# STM32U385 register map
File version: 1.0
CPU: CM33 r0p1, little endian, MPU, FPU, 4 interrupt priority bits
Registers are 32-bit, read-write, reset 0x0 unless marked. A register's access mark holds for its fields unless they carry their own. Offsets are from the block's base; [hi:lo] are bit positions; {n}, {i} and the like mark numbered series; 'fields as' and 'values as' point back to an identical list.

## USB — USB Address block
Base 0x40016000
Same registers: SEC_USB 0x50016000
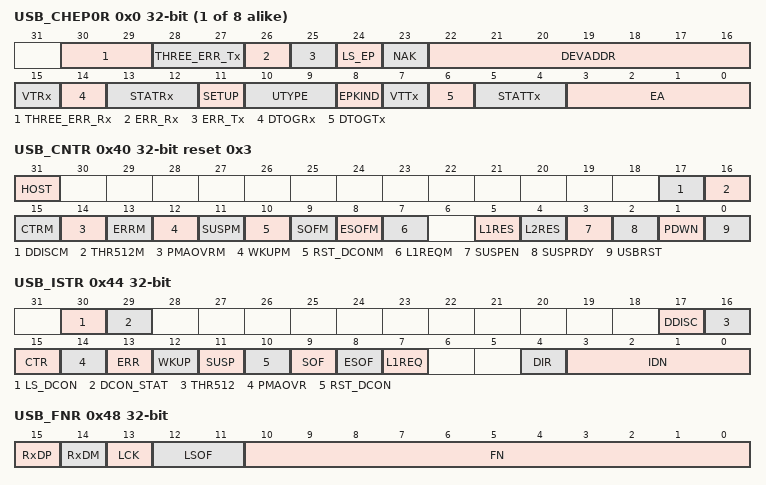
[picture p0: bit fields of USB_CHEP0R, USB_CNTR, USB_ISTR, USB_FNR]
{0x0+4i} USB_CHEP{i}R access per field (i=0..7) — USB endpoint/channel {i} register
  [30:29] THREE_ERR_Rx rw — - Host mode This bit is set by the hardware when 3 consecutive transaction errors occurred on the USB bus for an IN transaction. THREE_ERR_Rx is not generated for isochronous transactions. The software can only clear this bit. Coding of the received error: 00: Less than 3 errors received. 01: More than 3 errors received, last error is timeout error. 10: More than 3 errors received, last error is data error (CRC error). 11: More than 3 errors received, last error is protocol error (invalid PID, false EOP, bitstuffing error, SYNC error).
    0=Less than 3 errors received; 1=More than 3 errors received, last error is timeout error; 2=More than 3 errors received, last error is data error (CRC error); 3=More than 3 errors received, last error is protocol error (invalid PID, false EOP, bitstuffing error, SYNC error)
  [28:27] THREE_ERR_Tx rw — - Host mode This bit is set by the hardware when 3 consecutive transaction errors occurred on the USB bus for an OUT transaction. THREE_ERR_Tx is not generated for isochronous transactions. The software can only clear this bit. Coding of the received error: 00: Less than 3 errors received. 01: More than 3 errors received, last error is timeout error. 10: More than 3 errors received, last error is data error (CRC error). 11: More than 3 errors received, last error is protocol error (invalid PID, false EOP, bitstuffing error, SYNC error).
    values as THREE_ERR_Rx
  [26] ERR_Rx rw — - Host mode This bit is set by the hardware when an error (for example no answer by the device, CRC error, bit stuffing error, framing format violation, etc.) has occurred during an IN transaction on this channel. The software can only clear this bit. If the ERRM bit in USB_CNTR register is set, a generic interrupt condition is generated together with the channel related flag, which is always activated.
  [25] ERR_Tx rw — - Host mode This bit is set by the hardware when an error (for example no answer by the device, CRC error, bit stuffing error, framing format violation, etc.) has occurred during an OUT or SETUP transaction on this channel. The software can only clear this bit. If the ERRM bit in USB_CNTR register is set, a generic interrupt condition is generated together with the channel related flag, which is always activated.
  [24] LS_EP rw — - Host mode This bit is set by the software to send an LS transaction to the corresponding endpoint. 0: Full speed endpoint 1: Low speed endpoint
    0=Full speed endpoint; 1=Low speed endpoint
  [23] NAK rw — - Host mode This bit is set by the hardware when a device responds with a NAK. Software can use this bit to monitor the number of NAKs received from a device.
  [22:16] DEVADDR rw — - Host mode Device address assigned to the endpoint during the enumeration process.
  [15] VTRx rw — - Device mode This bit is set by the hardware when an OUT/SETUP transaction is successfully completed on this endpoint; the software can only clear this bit. If the CTRM bit in USB_CNTR register is set accordingly, a generic interrupt condition is generated together with the endpoint related interrupt condition, which is always activated. The type of occurred transaction, OUT or SETUP, can be determined from the SETUP bit described below. A transaction ended with a NAK or STALL handshake does not set this bit, since no data is actually transferred, as in the case of protocol errors or data toggle mismatches. This bit is read/write but only 0 can be written, writing 1 has no effect. - Host mode This bit is set by the hardware when an IN transaction is successfully completed on this channel. The software can only clear this bit. If the CTRM bit in USB_CNTR register is set a generic interrupt condition is generated together with the channel related flag, which is always activated. If double buffering is disabled, ACK answer is reported by application reading the DISABLE state from the STATRx field of this register. Host application should read received data from USBRAM and re-arm the channel by writing VALID to the STATRx field of this register. If double buffering is enabled, ACK answer is reported by application reading VALID state from the STATRx field of this register. Host application should read received data from USBRAM and toggle the DTOGTx bit of this register. Errors can be seen via the bits ERR_Rx (host mode only). This bit is read/write but only 0 can be written, writing 1 has no effect.
  [14] DTOGRx wo — If the endpoint/channel is not isochronous, this bit contains the expected value of the data toggle bit (0 = DATA0, 1 = DATA1) for the next data packet to be received. Hardware toggles this bit, when the ACK handshake is sent following a data packet reception having a matching data PID value; if the endpoint is defined as a control one, hardware clears this bit at the reception of a SETUP PID received from host (in device mode), while it sets this bit to 1 when SETUP transaction is acknowledged by device (in host mode). If the endpoint/channel is using the double-buffering feature this bit is used to support packet buffer swapping too (Refer to less than xe1 [Double-buffered_endpoints_and_usage_in_Device_mode]/>). If the endpoint/channel is isochronous, this bit is used only to support packet buffer swapping for data transmission since no data toggling is used for this kind of channels/endpoints and only DATA0 packet are transmitted (Refer to less than xe2 [Isochronous_transfers_in_Device_mode]/>). Hardware toggles this bit just after the end of data packet reception, since no handshake is used for isochronous transfers. This bit can also be toggled by the software to initialize its value (mandatory when the endpoint is not a control one) or to force specific data toggle/packet buffer usage. When the application software writes 0, the value of DTOGRx remains unchanged, while writing 1 makes the bit value toggle. This bit is read/write but it can be only toggled by writing 1. - A transaction ended with a NAK sets this bit and NAK answer is reported to application reading the NAK state from the STATRx field of this register. One NAKed transaction keeps pending and is automatically retried by the host at the next frame, or the host can immediately retry by resetting STATRx state to VALID. - A transaction ended by STALL handshake sets this bit and the STALL answer is reported to application reading the STALL state from the STATRx field of this register. Host application should consequently disable the channel and re-enumerate. - A transaction ended with ACK handshake sets this bit - A transaction ended with error sets this bit.
  [13:12] STATRx wo — - Device mode These bits contain information about the endpoint status, which are listed in less than xe3 []/>.
    0=DISABLED: all reception requests addressed to this endpoint/channel are ignored; 1=STALL: Device mode: the endpoint is stalled and all reception requests result in a STALL handshake. Host mode: this indicates that the device has STALLed the channel.; 2=NAK: Device mode: the endpoint is NAKed and all reception requests result in a NAK handshake. Host mode: this indicates that the device has NAKed the reception request.; 3=VALID: this endpoint/channel is enabled for reception
  [11] SETUP ro — - Device mode This bit is read-only and it is set by the hardware when the last completed transaction is a SETUP. This bit changes its value only for control endpoints. It must be examined, in the case of a successful receive transaction (VTRx event), to determine the type of transaction occurred. To protect the interrupt service routine from the changes in SETUP bits due to next incoming tokens, this bit is kept frozen while VTRx bit is at 1; its state changes when VTRx is at 0. This bit is read-only. - Host mode This bit is set by the software to send a SETUP transaction on a control endpoint. This bit changes its value only for control endpoints. It is cleared by hardware when the SETUP transaction is acknowledged and VTTx interrupt generated.
  [10:9] UTYPE rw — These bits configure the behavior of this endpoint/channel as described in less than xe4 []/>. Channel0/Endpoint0 must always be a control endpoint/channel and each USB function must have at least one control endpoint/channel which has address 0, but there may be other control channels/endpoints if required. Only control channels/endpoints handle SETUP transactions, which are ignored by endpoints of other kinds. SETUP transactions cannot be answered with NAK or STALL. If a control endpoint/channel is defined as NAK, the USB peripheral does not answer, simulating a receive error, in the receive direction when a SETUP transaction is received. If the control endpoint/channel is defined as STALL in the receive direction, then the SETUP packet is accepted anyway, transferring data and issuing the CTR interrupt. The reception of OUT transactions is handled in the normal way, even if the endpoint/channel is a control one. Bulk and interrupt endpoints have very similar behavior and they differ only in the special feature available using the EPKIND configuration bit. The usage of isochronous channels/endpoints is explained in less than xe2 [Isochronous_transfers_in_Device_mode]/> 00: BULK-EPKIND meaning : DBL_BUF 01: CONTROL-EPKIND meaning :STATUS_OUT 10: ISO-EPKIND meaning SBUF_ISO: This bit is set by the software to enable the single-buffering feature for isochronous endpoint 11: INTERRUPT-EPKIND meaning : Not used
    0=BULK-EPKIND meaning : DBL_BUF; 1=CONTROL-EPKIND meaning :STATUS_OUT; 2=ISO-EPKIND meaning SBUF_ISO: This bit is set by the software to enable the single-buffering feature for isochronous endpoint; 3=INTERRUPT-EPKIND meaning : Not used
  [8] EPKIND rw — The meaning of this bit depends on the endpoint/channel type configured by the UTYPE bits. less than xe5 []/> summarizes the different meanings. DBL_BUF: This bit is set by the software to enable the double-buffering feature for this bulk endpoint. The usage of double-buffered bulk endpoints is explained in less than xe1 [Double-buffered_endpoints_and_usage_in_Device_mode]/>. STATUS_OUT: This bit is set by the software to indicate that a status out transaction is expected: in this case all OUT transactions containing more than zero data bytes are answered 'STALL' instead of 'ACK'. This bit may be used to improve the robustness of the application to protocol errors during control transfers and its usage is intended for control endpoints only. When STATUS_OUT is reset, OUT transactions can have any number of bytes, as required.
  [7] VTTx rw — - Device mode This bit is set by the hardware when an IN transaction is successfully completed on this endpoint; the software can only clear this bit. If the CTRM bit in the USB_CNTR register is set accordingly, a generic interrupt condition is generated together with the endpoint related interrupt condition, which is always activated. A transaction ended with a NAK or STALL handshake does not set this bit, since no data is actually transferred, as in the case of protocol errors or data toggle mismatches. This bit is read/write but only 0 can be written. - Host mode Same as VTRx behavior but for USB OUT and SETUP transactions.
  [6] DTOGTx wo — If the endpoint/channel is non-isochronous, this bit contains the required value of the data toggle bit (0 = DATA0, 1 = DATA1) for the next data packet to be transmitted. Hardware toggles this bit when the ACK handshake is received from the USB host, following a data packet transmission. If the endpoint/channel is defined as a control one, hardware sets this bit to 1 at the reception of a SETUP PID addressed to this endpoint (in device mode) or when a SETUP transaction is acknowledged by the device (in host mode). If the endpoint/channel is using the double buffer feature, this bit is used to support packet buffer swapping too (Refer to less than xe1 [Double-buffered_endpoints_and_usage_in_Device_mode]/>). If the endpoint/channel is isochronous, this bit is used to support packet buffer swapping since no data toggling is used for this sort of endpoints and only DATA0 packet are transmitted (refer to less than xe2 [Isochronous_transfers_in_Device_mode]/>). Hardware toggles this bit just after the end of data packet transmission, since no handshake is used for isochronous transfers. This bit can also be toggled by the software to initialize its value (mandatory when the endpoint/channel is not a control one) or to force a specific data toggle/packet buffer usage. When the application software writes 0, the value of DTOGTx remains unchanged, while writing 1 makes the bit value to toggle. This bit is read/write but it can only be toggled by writing 1.
  [5:4] STATTx wo — - Device mode These bits contain the information about the endpoint status, listed in less than xe6 []/>.
    0=DISABLED: all transmission requests addressed to this endpoint/channel are ignored; 1=STALL: Device mode: the endpoint is stalled and all transmission requests result in a STALL handshake. Host mode: this indicates that the device has STALLed the channel.; 2=NAK: Device mode: the endpoint is NAKed and all transmission requests result in a NAK handshake. Host mode: this indicates that the device has NAKed the transmission request.; 3=VALID: this endpoint/channel is enabled for transmission
  [3:0] EA rw — - Device mode Software must write in this field the 4-bit address used to identify the transactions directed to this endpoint. A value must be written before enabling the corresponding endpoint. - Host mode Software must write in this field the 4-bit address used to identify the channel addressed by the host transaction.
0x40 USB_CNTR access per field reset 0x3 — USB control register
  [31] HOST rw — HOST bit selects betweens host or device USB mode of operation. It must be set before enabling the USB peripheral by the function enable bit. 0: USB Device function 1: USB host function
    0=USB Device function; 1=USB host function
  [17] DDISCM rw — - Host mode 0: Device disconnection interrupt disabled 1: Device disconnection interrupt enabled
    0=Device disconnection interrupt disabled; 1=Device disconnection interrupt enabled
  [16] THR512M rw — None 0: 512 byte threshold interrupt disabled 1: 512 byte threshold interrupt enabled
    0=512 byte threshold interrupt disabled; 1=512 byte threshold interrupt enabled
  [15] CTRM rw — None 0: Correct transfer (CTR) interrupt disabled. 1: CTR interrupt enabled, an interrupt request is generated when the corresponding bit in the USB_ISTR register is set.
    0=Correct transfer (CTR) interrupt disabled; 1=CTR interrupt enabled, an interrupt request is generated when the corresponding bit in the USB_ISTR register is set
  [14] PMAOVRM rw — None 0: PMAOVR interrupt disabled. 1: PMAOVR interrupt enabled, an interrupt request is generated when the corresponding bit in the USB_ISTR register is set.
    0=PMAOVR interrupt disabled; 1=PMAOVR interrupt enabled, an interrupt request is generated when the corresponding bit in the USB_ISTR register is set
  [13] ERRM rw — None 0: ERR interrupt disabled. 1: ERR interrupt enabled, an interrupt request is generated when the corresponding bit in the USB_ISTR register is set.
    0=ERR interrupt disabled; 1=ERR interrupt enabled, an interrupt request is generated when the corresponding bit in the USB_ISTR register is set
  [12] WKUPM rw — None 0: WKUP interrupt disabled. 1: WKUP interrupt enabled, an interrupt request is generated when the corresponding bit in the USB_ISTR register is set.
    0=WKUP interrupt disabled; 1=WKUP interrupt enabled, an interrupt request is generated when the corresponding bit in the USB_ISTR register is set
  [11] SUSPM rw — None 0: Suspend mode request (SUSP) interrupt disabled. 1: SUSP interrupt enabled, an interrupt request is generated when the corresponding bit in the USB_ISTR register is set.
    0=Suspend mode request (SUSP) interrupt disabled; 1=SUSP interrupt enabled, an interrupt request is generated when the corresponding bit in the USB_ISTR register is set
  [10] RST_DCONM rw — None 0: RESET interrupt disabled. 1: RESET interrupt enabled, an interrupt request is generated when the corresponding bit in the USB_ISTR register is set.
    0=RESET interrupt disabled; 1=RESET interrupt enabled, an interrupt request is generated when the corresponding bit in the USB_ISTR register is set
  [9] SOFM rw — None 0: SOF interrupt disabled. 1: SOF interrupt enabled, an interrupt request is generated when the corresponding bit in the USB_ISTR register is set.
    0=SOF interrupt disabled; 1=SOF interrupt enabled, an interrupt request is generated when the corresponding bit in the USB_ISTR register is set
  [8] ESOFM rw — None 0: Expected start of frame (ESOF) interrupt disabled. 1: ESOF interrupt enabled, an interrupt request is generated when the corresponding bit in the USB_ISTR register is set.
    0=Expected start of frame (ESOF) interrupt disabled; 1=ESOF interrupt enabled, an interrupt request is generated when the corresponding bit in the USB_ISTR register is set
  [7] L1REQM rw — None 0: LPM L1 state request (L1REQ) interrupt disabled. 1: L1REQ interrupt enabled, an interrupt request is generated when the corresponding bit in the USB_ISTR register is set.
    0=LPM L1 state request (L1REQ) interrupt disabled; 1=L1REQ interrupt enabled, an interrupt request is generated when the corresponding bit in the USB_ISTR register is set
  [5] L1RES rw — - Device mode Software sets this bit to send a LPM L1 50 us remote wakeup signaling to the host. After the signaling ends, this bit is cleared by hardware. 0: No effect 1: Send 50 us remote-wakeup signaling to host
    0=No effect; 1=Send 50 us remote-wakeup signaling to host
  [4] L2RES rw — - Device mode The microcontroller can set this bit to send remote wake-up signaling to the host. It must be activated, according to USB specifications, for no less than 1 ms and no more than 15 ms after which the host PC is ready to drive the resume sequence up to its end. - Host mode Software sets this bit to send resume signaling to the device. Software clears this bit to send end of resume to device and restart SOF generation. In the context of remote wake up, this bit is to be set following the WAKEUP interrupt. 0: No effect 1: Send L2 resume signaling to device
    0=No effect; 1=Send L2 resume signaling to device
  [3] SUSPEN rw — - Condition: Device mode Software can set this bit when the SUSP interrupt is received, which is issued when no traffic is received by the USB peripheral for 3 ms. Software can also set this bit when the L1REQ interrupt is received with positive acknowledge sent. As soon as the suspend state is propagated internally all device activity is stopped, USB clock is gated, USB transceiver is set into low power mode and the SUSPRDY bit is set by hardware. In the case that device application wants to pursue more aggressive power saving by stopping the USB clock source and by moving the microcontroller to stop mode, as in the case of bus powered device application, it must first wait few cycles to see the SUSPRDY = 1 acknowledge the suspend request. This bit is cleared by hardware simultaneous with the WAKEUP flag set. Software can set this bit when host application has nothing scheduled for the next frames and wants to enter long term power saving. When set, it stops immediately SOF generation and any other host activity, gates the USB clock and sets the transceiver in low power mode. If any USB transaction is on-going at the time SUSPEN is set, suspend is entered at the end of the current transaction. As soon as suspend state is propagated internally and gets effective the SUSPRDY bit is set. In the case that host application wants to pursue more aggressive power saving by stopping the USB clock source and by moving the micro-controller to STOP mode, it must first wait few cycles to see SUSPRDY=1 acknowledge to the suspend request. This bit is cleared by hardware simultaneous with the WAKEUP flag set. Condition: Device mode 0: No effect 1: Enter L1/L2 suspend Condition: Host mode 0: No effect 1: Enter L1/L2 suspend
    0=B_0x0_COND1 (COND1 is [Device mode] No effect); 1=B_0x1_COND1 (COND1 is [Device mode] Enter L1/L2 suspend)
  [2] SUSPRDY ro — This bit is set by hardware as soon as the suspend state entered through the SUSPEN control gets internally effective. In this state USB activity is suspended, USB clock is gated, transceiver is set in low power mode by disabling the differential receiver. Only asynchronous wakeup logic and single ended receiver is kept alive to detect remote wakeup or resume events. Software must poll this bit to confirm it to be set before any STOP mode entry. This bit is cleared by hardware simultaneously to the WAKEUP flag being set. 0: Normal operation 1: Suspend state
    0=Normal operation; 1=Suspend state
  [1] PDWN rw — This bit is used to completely switch off all USB-related analog parts if it is required to completely disable the USB peripheral for any reason. When this bit is set, the USB peripheral is disconnected from the transceivers and it cannot be used. 0: Exit power down 1: Enter power down mode
    0=Exit power down; 1=Enter power down mode
  [0] USBRST rw — - Condition: Device mode Software can set this bit to reset the USB core, exactly as it happens when receiving a RESET signaling on the USB.The USB peripheral, in response to a RESET, resets its internal protocol state machine. Reception and transmission are disabled until the RST_DCON bit is cleared. All configuration registers do not reset: the microcontroller must explicitly clear these registers (this is to ensure that the RST_DCON interrupt can be safely delivered, and any transaction immediately followed by a RESET can be completed). The function address and endpoint registers are reset by an USB reset event. Software sets this bit to drive USB reset state on the bus and initialize the device. USB reset terminates as soon as this bit is cleared by software. Condition: Device mode 0: No effect 1: USB core is under reset Condition: Host mode 0: No effect 1: USB reset driven
    0=B_0x0_COND1 (COND1 is [Device mode] No effect); 1=B_0x1_COND1 (COND1 is [Device mode] USB core is under reset)
0x44 USB_ISTR access per field — USB interrupt status register
  [30] LS_DCON ro — - Host mode: This bit is set by hardware when an LS device connection is detected. Device connection is signaled after LS J-state is sampled for 22 consecutive cycles of the USB clock (48 MHz) from the unconnected state.
  [29] DCON_STAT ro — - Host mode: This bit contains information about device connection status. It is set by hardware when a LS/FS device is attached to the host while it is reset when the device is disconnected. 0: No device connected 1: FS or LS device connected to the host
    0=No device connected; 1=FS or LS device connected to the host
  [17] DDISC rw — - Host mode This bit is set when a device connection is detected. This bit is read/write but only 0 can be written and writing 1 has no effect.
  [16] THR512 rw — This bit is set to 1 by the hardware when 512 bytes have been transmitted or received during isochronous transfers. This bit is read/write but only 0 can be written and writing 1 has no effect. Note that no information is available to indicate the associated channel/endpoint, however in practice only one ISO endpoint/channel with such large packets can be supported, so that channel.
  [15] CTR ro — This bit is set by the hardware to indicate that an endpoint/channel has successfully completed a transaction; using DIR and IDN bits software can determine which endpoint/channel requested the interrupt. This bit is read-only.
  [14] PMAOVR rw — This bit is set if the microcontroller has not been able to respond in time to an USB memory request. The USB peripheral handles this event in the following way: During reception an ACK handshake packet is not sent, during transmission a bit-stuff error is forced on the transmitted stream; in both cases the host retries the transaction. The PMAOVR interrupt should never occur during normal operations. Since the failed transaction is retried by the host, the application software has the chance to speed-up device operations during this interrupt handling, to be ready for the next transaction retry; however this does not happen during isochronous transfers (no isochronous transaction is anyway retried) leading to a loss of data in this case. This bit is read/write but only 0 can be written and writing 1 has no effect.
  [13] ERR rw — This flag is set whenever one of the errors listed below has occurred: NANS:No ANSwer. The timeout for a host response has expired. CRC:Cyclic redundancy check error. One of the received CRCs, either in the token or in the data, was wrong. BST:Bit stuffing error. A bit stuffing error was detected anywhere in the PID, data, and/or CRC. FVIO:Framing format violation. A non-standard frame was received (EOP not in the right place, wrong token sequence, etc.). The USB software can usually ignore errors, since the USB peripheral and the PC host manage retransmission in case of errors in a fully transparent way. This interrupt can be useful during the software development phase, or to monitor the quality of transmission over the USB bus, to flag possible problems to the user (for example loose connector, too noisy environment, broken conductor in the USB cable and so on). This bit is read/write but only 0 can be written and writing 1 has no effect.
  [12] WKUP rw — This bit is set to 1 by the hardware when, during suspend mode, activity is detected that wakes up the USB peripheral. This event asynchronously clears the SUSPRDY bit in the CTLR register and activates the USB_WAKEUP line, which can be used to notify the rest of the device (for example wakeup unit) about the start of the resume process. This bit is read/write but only 0 can be written and writing 1 has no effect.
  [11] SUSP rw — - Device mode This bit is set by the hardware when no traffic has been received for 3 ms, indicating a suspend mode request from the USB bus. The suspend condition check is enabled immediately after any USB reset and it is disabled by the hardware when the suspend mode is active (SUSPEN=1) until the end of resume sequence. This bit is read/write but only 0 can be written and writing 1 has no effect.
  [10] RST_DCON rw — - Device mode This bit is set by hardware when an USB reset is released by the host and the bus returns to idle. USB reset state is internally detected after the sampling of 60 consecutive SE0 cycles. - Host mode This bit is set by hardware when device connection or device disconnection is detected. Device connection is signaled after J state is sampled for 22 cycles consecutively from unconnected state. Device disconnection is signaled after SE0 state is seen for 22 bit times consecutively from connected state.
  [9] SOF rw — This bit signals the beginning of a new USB frame and it is set when a SOF packet arrives through the USB bus. The interrupt service routine may monitor the SOF events to have a 1 ms synchronization event to the USB host and to safely read the USB_FNR register which is updated at the SOF packet reception (this could be useful for isochronous applications). This bit is read/write but only 0 can be written and writing 1 has no effect.
  [8] ESOF rw — - Device mode This bit is set by the hardware when an SOF packet is expected but not received. The host sends an SOF packet each 1 ms, but if the device does not receive it properly, the suspend timer issues this interrupt. If three consecutive ESOF interrupts are generated (for example three SOF packets are lost) without any traffic occurring in between, a SUSP interrupt is generated. This bit is set even when the missing SOF packets occur while the suspend timer is not yet locked. This bit is read/write but only 0 can be written and writing 1 has no effect.
  [7] L1REQ rw — - Device mode This bit is set by the hardware when LPM command to enter the L1 state is successfully received and acknowledged. This bit is read/write but only 0 can be written and writing 1 has no effect.
  [4] DIR ro — This bit is written by the hardware according to the direction of the successful transaction, which generated the interrupt request. If DIR bit = 0, VTTx bit is set in the USB_CHEPnR register related to the interrupting endpoint. The interrupting transaction is of IN type (data transmitted by the USB peripheral to the host PC). If DIR bit = 1, VTRx bit or both VTTx/VTRx are set in the USB_CHEPnR register related to the interrupting endpoint. The interrupting transaction is of OUT type (data received by the USB peripheral from the host PC) or two pending transactions are waiting to be processed. This information can be used by the application software to access the USB_CHEPnR bits related to the triggering transaction since it represents the direction having the interrupt pending. This bit is read-only.
  [3:0] IDN ro — These bits are written by the hardware according to the host channel or device endpoint number, which generated the interrupt request. If several endpoint/channel transactions are pending, the hardware writes the identification number related to the endpoint/channel having the highest priority defined in the following way: two levels are defined, in order of priority: isochronous and double-buffered bulk channels/endpoints are considered first and then the others are examined. If more than one endpoint/channel from the same set is requesting an interrupt, the IDN bits in USB_ISTR register are assigned according to the lowest requesting register, CHEP0R having the highest priority followed by CHEP1R and so on. The application software can assign a register to each endpoint/channel according to this priority scheme, so as to order the concurring endpoint/channel requests in a suitable way. These bits are read only.
0x48 USB_FNR ro (reset mask 0xFFFFF000) — USB frame number register
  [15] RxDP — This bit can be used to observe the status of received data plus upstream port data line. It can be used during end-of-suspend routines to help determining the wakeup event.
  [14] RxDM — This bit can be used to observe the status of received data minus upstream port data line. It can be used during end-of-suspend routines to help determining the wakeup event.
  [13] LCK — - Device mode This bit is set by the hardware when at least two consecutive SOF packets have been received after the end of an USB reset condition or after the end of an USB resume sequence. Once locked, the frame timer remains in this state until an USB reset or USB suspend event occurs.
  [12:11] LSOF — - Device mode These bits are written by the hardware when an ESOF interrupt is generated, counting the number of consecutive SOF packets lost. At the reception of an SOF packet, these bits are cleared.
  [10:0] FN — This bit field contains the 11-bits frame number contained in the last received SOF packet. The frame number is incremented for every frame sent by the host and it is useful for isochronous transfers. This bit field is updated on the generation of an SOF interrupt.
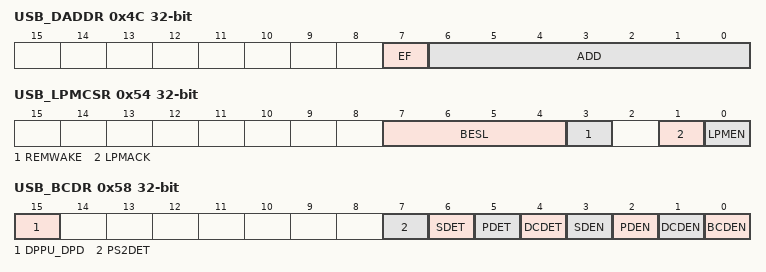
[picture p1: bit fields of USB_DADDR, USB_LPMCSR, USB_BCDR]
0x4C USB_DADDR — USB Device address
  [7] EF — This bit is set by the software to enable the USB Device. The address of this device is contained in the following ADD[6:0] bits. If this bit is at 0 no transactions are handled, irrespective of the settings of USB_CHEPnR registers.
  [6:0] ADD — - Device mode These bits contain the USB function address assigned by the host PC during the enumeration process. Both this field and the endpoint/channel address (EA) field in the associated USB_CHEPnR register must match with the information contained in a USB token in order to handle a transaction to the required endpoint. - Host mode These bits contain the address transmitted with the LPM transaction
0x54 USB_LPMCSR access per field — LPM control and status register
  [7:4] BESL ro — - Device mode These bits contain the BESL value received with last ACKed LPM Token
  [3] REMWAKE ro — - Device mode This bit contains the bRemoteWake value received with last ACKed LPM Token
  [1] LPMACK rw — - Device mode: The NYET/ACK is returned only on a successful LPM transaction: No errors in both the ExT token and the LPM token (else ERROR) A valid bLinkState = 0001B (L1) is received (else STALL) 0: the valid LPM token is NYET. 1: the valid LPM token is ACK.
    0=the valid LPM token is NYET; 1=the valid LPM token is ACK
  [0] LPMEN rw — - Device mode This bit is set by the software to enable the LPM support within the USB Device. If this bit is at 0 no LPM transactions are handled.
0x58 USB_BCDR access per field — Battery charging detector
  [15] DPPU_DPD rw — - Device mode This bit is set by software to enable the embedded pull-up on DP line. Clearing it to 0 can be used to signal disconnect to the host when needed by the user software. - Host mode This bit is set by software to enable the embedded pull-down on DP and DM lines.
  [7] PS2DET ro — - Device mode This bit is active only during PD and gives the result of comparison between DM voltage level and VLGC threshold. In normal situation, the DM level should be below this threshold. If it is above, it means that the DM is externally pulled high. This can be caused by connection to a PS2 port (which pulls-up both DP and DM lines) or to some proprietary charger not following the BCD specification. 0: Normal port detected (connected to SDP, ACA, CDP or DCP). 1: PS2 port or proprietary charger detected.
    0=Normal port detected (connected to SDP, ACA, CDP or DCP); 1=PS2 port or proprietary charger detected
  [6] SDET ro — - Device mode This bit gives the result of SD. 0: CDP detected. 1: DCP detected.
    0=CDP detected; 1=DCP detected
  [5] PDET ro — - Device mode This bit gives the result of PD. 0: no BCD support detected (connected to SDP or proprietary device). 1: BCD support detected (connected to ACA, CDP or DCP).
    0=no BCD support detected (connected to SDP or proprietary device); 1=BCD support detected (connected to ACA, CDP or DCP)
  [4] DCDET ro — - Device mode This bit gives the result of DCD. 0: data lines contact not detected. 1: data lines contact detected.
    0=data lines contact not detected; 1=data lines contact detected
  [3] SDEN rw — - Device mode This bit is set by the software to put the BCD into SD mode. Only one detection mode (DCD, PD, SD or OFF) should be selected to work correctly.
  [2] PDEN rw — - Device mode This bit is set by the software to put the BCD into PD mode. Only one detection mode (DCD, PD, SD or OFF) should be selected to work correctly.
  [1] DCDEN rw — - Device mode This bit is set by the software to put the BCD into DCD mode. Only one detection mode (DCD, PD, SD or OFF) should be selected to work correctly.
  [0] BCDEN rw — - Device mode This bit is set by the software to enable the BCD support within the USB Device. When enabled, the USB PHY is fully controlled by BCD and cannot be used for normal communication. Once the BCD discovery is finished, the BCD should be placed in OFF mode by clearing this bit to 0 in order to allow the normal USB operation.
